# CSI2_PROTOCOL_ENGINE register map
Vendor: Texas Instruments
Peripheral module from a debugger description file (folder awr2544).
Registers are 32-bit, access per field, no defined reset value unless marked. A register's access mark holds for its fields unless they carry their own. Offsets are as the file gives them; lines under a group give offsets from that group; [hi:lo] are bit positions; {n}, {i} and the like mark numbered series; 'fields as' and 'values as' point back to an identical list; <NAME> marks a mode.

## CSI2_PROTOCOL_ENGINE (part 1 of 2) — CSI2 protocol engine (MIPI Display Serial Interface Protocole)
0x00 CSI2_REVISION ro — MODULE REVISION This register contains the IP revision code in binary coded digital. For example, we have: 0x01 = revision 0.1 and 0x21 = revision 2.1
  [7:0] REV — IP revision [7:4] Major revision [3:0] Minor revision
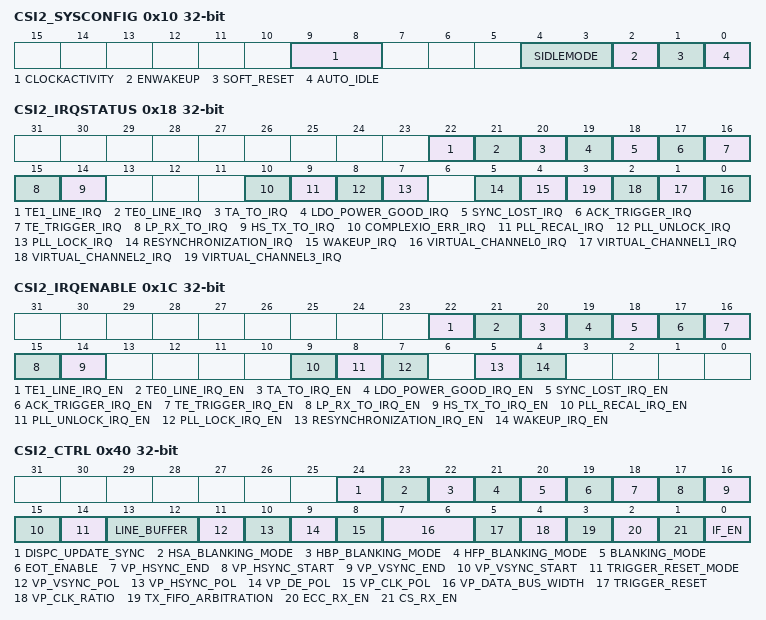
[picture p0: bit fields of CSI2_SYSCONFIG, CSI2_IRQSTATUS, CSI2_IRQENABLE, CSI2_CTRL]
0x10 CSI2_SYSCONFIG — SYSTEM CONFIGURATION REGISTER This register is the OCP-socket system configuration register.
  [9:8] CLOCKACTIVITY rw — Clocks activity during wake up mode period
    0=OCPFUNCOFF (OCP and Functional clocks can be switched off); 1=FUNCOFF (Functional clocks can be switched off and OCP clocks are maintained during wake up period); 2=OCPOFF (OCP clocks can be switched off and Functional clocks are maintained during wake up period); 3=OCPFUNCON (OCP and Functional clocks are maintained during wake up period)
  [4:3] SIDLEMODE rw — Slave interface power management, Idle req/ack control
    0=FIDLE (Force-idle. An idle request is acknowledged unconditionally); 1=NIDLE (No-idle. An idle request is never acknowledged); 2=SIDLE (Smart-idle. Acknowledgement to an idle request is given based on the internal activity of the module.)
  [2] ENWAKEUP rw — Wake-up mode enable bit
    0=WAKEUPDIS (Wakeup is disabled); 1=WAKEUPENB (Wakeup is enabled)
  [1] SOFT_RESET rw — Software reset. Set the bit to 1 to trigger a module reset. The bit is automatically reset by the hw. During reads return 0.
    0=NORMAL (Normal mode.); 1=RESET (The module is reset)
  [0] AUTO_IDLE rw — Internal OCP gating strategy
    0=FREE (OCP clock is free-running.); 1=GATED (Automatic OCP clock gating strategy is applied based on the OCP interface activity.)
0x14 CSI2_SYSSTATUS ro — SYSTEM STATUS REGISTER This register provides status information about the module, excluding the interrupt status register.
  [0] RESET_DONE — Internal reset monitoring
    0=RESETONGOING (Internal module reset is on going.); 1=RESETCOMPLETED
0x18 CSI2_IRQSTATUS — INTERRUPT STATUS REGISTER - All virtual channels + Complex IO + PLL This register associates one bit for each virtual channel in order to determine which virtual channel has generated the interrupt. The virtual channel shall be enabled for events to be generated on that virtual channel. If the virtual channel is disabled, the interrupt is not generated.
  [22] TE1_LINE_IRQ rw — The VSYNC and corresponding HSYNC pulses defined in CSI2_TE_HSYNC_NUMBER for the line TE1 have been received by the CSI2 protocol engine and have trigger the start of the data transfer to the peripheral.
    0=FALSE (READS: Event is false. WRITES: Status bit unchanged.); 1=TRUE (READS: Event is true (pending). WRITES: Status bit is reset.)
  [21] TE0_LINE_IRQ rw — The VSYNC and corresponding HSYNC pulses defined in CSI2_TE_HSYNC_NUMBER for the line TE0 have been received by the CSI2 protocol engine and have trigger the start of the data transfer to the peripheral.
    values as TE1_LINE_IRQ
  [20] TA_TO_IRQ rw — Turn-around Time out.
    values as TE1_LINE_IRQ
  [19] LDO_POWER_GOOD_IRQ rw — Transition of the status signal LDOPWRGOOD from the CSI2PHY indicating a state change for the supply VDDALDOCSI2PLL from up to down or down to up.
    values as TE1_LINE_IRQ
  [18] SYNC_LOST_IRQ rw — Synchronization with Video port is lost (Video mode only)
    values as TE1_LINE_IRQ
  [17] ACK_TRIGGER_IRQ rw — Acknowledge Trigger
    values as TE1_LINE_IRQ
  [16] TE_TRIGGER_IRQ rw — Tearing Effect Trigger
    values as TE1_LINE_IRQ
  [15] LP_RX_TO_IRQ rw — Interrupt for Low Power Rx Time out
    values as TE1_LINE_IRQ
  [14] HS_TX_TO_IRQ rw — Interrupt for High Speed Tx Time out.
    values as TE1_LINE_IRQ
  [10] COMPLEXIO_ERR_IRQ ro — Error signaling from Complex IO: status of the complex IO errors received from the complex IO(events are defined in CSI2_COMPLEXIO_IRQSTATUS).
    0=FALSE (READS: Event is false.); 1=TRUE (READS: Event is true (pending).)
  [9] PLL_RECAL_IRQ rw — PLL recal event (assertion of CSI2Recal signal from the CSI2 PLL Control module)
    values as TE1_LINE_IRQ
  [8] PLL_UNLOCK_IRQ rw — PLL un-clock event (de-assertion of CSI2Lock signal from the CSI2 PLL Control module)
    values as TE1_LINE_IRQ
  [7] PLL_LOCK_IRQ rw — PLL clock event (assertion of CSI2Lock signal from the CSI2 PLL Control module)
    values as TE1_LINE_IRQ
  [5] RESYNCHRONIZATION_IRQ rw — Video mode resynchronization indicates to the software users that the video port works but the configuration of the timings for the display controller (DISPC) and for CSI2 Protocol engine may need to be modified to avoid the resynchronization to occur.
    values as TE1_LINE_IRQ
  [4] WAKEUP_IRQ rw — Wakeup
    values as TE1_LINE_IRQ
  [n] VIRTUAL_CHANNEL{n}_IRQ ro (n=0..3) — Virtual channel #{n}
    values as COMPLEXIO_ERR_IRQ
0x1C CSI2_IRQENABLE — INTERRUPT ENABLE REGISTER - This register associates one bit for each virtual channel in order to enable/disable each virtual channel individually.
  [all] fields
    0=DISABLE (Event is masked); 1=ENABLE (Event generates an interrupt when it occurs)
  [22] TE1_LINE_IRQ_EN rw — The VSYNC and corresponding HSYNC pulses defined in CSI2_TE_HSYNC_NUMBER for the line TE1 have been received by the CSI2 protocol engine and have trigger the start of the data transfer to the peripheral.
  [21] TE0_LINE_IRQ_EN rw — The VSYNC and corresponding HSYNC pulses defined in CSI2_TE_HSYNC_NUMBER for the line TE0 have been received by the CSI2 protocol engine and have trigger the start of the data transfer to the peripheral.
  [20] TA_TO_IRQ_EN rw — Turn-around Time out.
  [19] LDO_POWER_GOOD_IRQ_EN rw — Transition of the status signal LDOPWRGOOD from the CSI2PHY indicating a state change for the supply VDDALDOCSI2PLL from up to down or down to up.
  [18] SYNC_LOST_IRQ_EN rw — Synchronization with Video port is lost (Video mode only)
  [17] ACK_TRIGGER_IRQ_EN rw — Acknowledge trigger
  [16] TE_TRIGGER_IRQ_EN rw — Tearing Effect trigger
  [15] LP_RX_TO_IRQ_EN rw — Interrupt for Low Power Rx Time out.
  [14] HS_TX_TO_IRQ_EN rw — Interrupt for High Speed Tx Time out.
  [9] PLL_RECAL_IRQ_EN rw — PLL recal event (assertion of CSI2Recal signal from the CSI2 PLL Control module)
  [8] PLL_UNLOCK_IRQ_EN rw — PLL un-clock event (de-assertion of CSI2Lock signal from the CSI2 PLL Control module)
  [7] PLL_LOCK_IRQ_EN rw — PLL clock event (assertion of CSI2Lock signal from the CSI2 PLL Control module)
  [5] RESYNCHRONIZATION_IRQ_EN rw — Video mode resynchronization
  [4] WAKEUP_IRQ_EN rw — Wakeup
0x40 CSI2_CTRL — GLOBAL CONTROL REGISTER This register controls the CSI2 Protocol Engine module. This register shall not be modified dynamically (except IF_EN bit fields).
  [24] DISPC_UPDATE_SYNC rw — Determines if the Dispc_Update_Sync signal from the display controller is used.
    0=DISABLE (Dispc_Update_Sync signal is not used.); 1=ENABLE (Dispc_Update_Sync signal is used.)
  [23] HSA_BLANKING_MODE rw — Blanking mode
    0=COMMAND_PACKET_TX_FIFO (Packets in TX FIFO are sent during HSA blanking period of video mode or LPS is used.); 1=HS_BLANKING_PACKET_ONLY (LONG BLANKING PACKETS only are used during HSA blanking period of video mode.)
  [22] HBP_BLANKING_MODE rw — Blanking mode
    0=COMMAND_PACKET_TX_FIFO (Packets in TX FIFO are sent during HBP blanking period of video mode or LPS is used.); 1=HS_BLANKING_PACKET_ONLY (LONG BLANKING PACKETS only are used during HBP blanking period of video mode.)
  [21] HFP_BLANKING_MODE rw — Blanking mode
    0=COMMAND_PACKET_TX_FIFO (Packets in TX FIFO are sent during HFP blanking period of video mode or LPS is used.); 1=HS_BLANKING_PACKET_ONLY (LONG BLANKING PACKETS only are used during HFP blanking period of video mode.)
  [20] BLANKING_MODE rw
    0=LPS (LPS is used during blanking periods of video mode (except HSA, HBP, HFP defined in HSA_BLANKING_MODE, HBP_BLANKING_MODE AND HFP_BLANKING_MODE respectively) when there is no command mode data in TX FIFO ready to be sent. So blanking periods can be different during the frame depending on the TX FIFO.); 1=HS (LONG BLANKING PACKETS are used during blanking periods of video mode (except HSA, HBP, HFP defined in HSA_BLANKING_MODE, HBP_BLANKING_MODE AND HFP_BLANKING_MODE respectively) regardless of the packets present in the TX FIFO ready to be sent)
  [19] EOT_ENABLE rw — Enable EOT packets at the end of HS transmission.
    0=EOT_OFF (No EOT packets); 1=EOT_ON (EOT packet is sent at all HS to LP transitions.)
  [18] VP_HSYNC_END rw — HSYNC end pulse.
    0=DISABLE (Disabled. No HSYNC END short packet is generated.); 1=ENABLE (Enabled. While the HSYNC END pulse is detected, the associated short packet HSYNC END is generated.)
  [17] VP_HSYNC_START rw — HSYNC start pulse.
    0=DISABLE (Disabled. No HSYNC START short packet is generated.); 1=ENABLE (Enabled. While the HSYNC start pulse is detected, the associated short packet HSYNC START is generated.)
  [16] VP_VSYNC_END rw — VSYNC end pulse.
    0=DISABLE (Disabled. No VSYNC END short packet is generated.); 1=ENABLE (Enabled. While the VSYNC END pulse is detected, the associated short packet VSYNC END is generated.)
  [15] VP_VSYNC_START rw — VSYNC start pulse.
    0=DISABLE (Disabled. No VSYNC START short packet is generated.); 1=ENABLE (Enabled. While the VSYNC START pulse is detected, the associated short packet VSYNC START is generated.)
  [14] TRIGGER_RESET_MODE rw — Selection of the trigger reset mode
    0=SYNCHRONIZED (Synchronized: the mode is only valid if there is virtual channel using the video mode and it is active. The principal is to wait for the current video frame to be transferred on the link. Any data received after the VSYNC are ignored.); 1=IMMEDIATE (Immediate: all pending requests in TX FIFO are taken into account for transfer scheduling, the RX FIFO is ignored, and the data from video port are ignored as soon as possible. Only the current transfer on CSI2 link and already scheduled ones are transmitted. All the other transfers are discarded.)
  [13:12] LINE_BUFFER rw — Number of line buffers to be used while receiving data on the video port. The valid values are from 0 to CSI2_GNQ.VP1_NB_LINE_BUFFER.
    0=F0 (No line buffer); 1=F1 (1 line buffer); 2=F2 (2 line buffers)
  [11] VP_VSYNC_POL rw — VP vertical synchronization signal polarity
    0=LOW (VSYNC signal on the video port is active low.); 1=HIGH (VSYNC signal on the video port is active high.)
  [10] VP_HSYNC_POL rw — VP horizontal synchronization signal polarity
    0=LOW (HSYNC signal on the video port is active low.); 1=HIGH (HSYNC signal on the video port is active high.)
  [9] VP_DE_POL rw — VP data enable signal polarity
    0=LOW (DE signal on the video port is active low.); 1=HIGH (DE signal on the video port is active high.)
  [8] VP_CLK_POL rw — VP clock polarity
    0=FALLING (The CSI2 Protocol Engine module captures the data on the VP on the pixel clock falling edge. The module connected to the VP shall drive the data on the pixel clock rising edge.); 1=RISING (The CSI2 Protocol Engine module captures the data on the VP on the pixel clock raising edge. The module connected to the VP shall drive the data on the pixel clock falling edge.)
  [7:6] VP_DATA_BUS_WIDTH rw — Defines the size of the video port data bus
    0=F16 (16-bits data width (LSB of the 24-bit video port data bus)); 1=F18 (18-bits data width (LSB of the 24-bit video port data bus)); 2=F24 (24-bits data width (LSB of the 24-bit video port data bus))
  [5] TRIGGER_RESET rw — Send the reset trigger to the peripheral.
    0=DISABLE (READS: Reset trigger generation is completed. It is reset by HW when it is completed. WRITES: Cancellation of the request for Reset trigger generation (maybe too late since it is already on going)); 1=ENABLE (READS: Generation of the reset trigger has been requested by user (could be on going but not completed yet). WRITES: Request for Reset trigger to be sent to the peripheral.)
  [4] VP_CLK_RATIO rw — The field indicates the clock ratio between VP.CLK and VP.PCLK. The clock VP.PCLK is generated from VP.CLK. It is divided down. The information is only used when the video port is used to provide data in command mode. In the case of video mode, it is not used.
    0=RATIO2 (The clock VP.PCLK is the clock VP.CLK divided by 2. The duty cycle of VP.PCLK is 50/50.); 1=RATIO3ANDHIGHER (The clock VP.PCLK is the clock VP.CLK divided by 3 or more. The duty cycle of VP.PCLK is not 50/50 for odd ratio numbers (3,5,7,...).)
  [3] TX_FIFO_ARBITRATION rw — Defines the arbitration scheme for granting the virtual channel pending ready requests in the TX FIFO
    0=ROUNDROBIN (Round-Robin Scheme is used); 1=SEQUENTIAL (Sequential Scheme is used)
  [2] ECC_RX_EN rw — Enables the Error Correction Code check for the received header (short and long packets for all virtual channel ids).
    0=DISABLE (Disabled); 1=ENABLE (Enabled)
  [1] CS_RX_EN rw — Enables the checksum check for the received payload (long packet only for all virtual channel ids).
    0=DISABLE (Disabled); 1=ENABLE (Enabled)
  [0] IF_EN rw — Enables the module. When the module is disabled the signals from the complex IO are gated (no updates of the interrupt status register). It is not possible to change the bit-fields in the register CSI2_CTRL except IF_EN when it is enabled. All the other registers can be changed except the ones that require CSI2_VC_CTRL.VC_EN to be equal to 0 to be modified.
    0=DISABLE (The interface is disabled. If one of the virtual channel uses the video mode with the video port to receive the data, the CSI2 protocol engines is disabled when the next VSYNC is received and all the data in the FIFO for the other virtual channels in command mode are sent to the peripherals (if BTA_EN is enabled, the CSI2 protocol needs to wait for the response and BTA from the peripheral before disabling all the internal logic since an acknowledge is requested).); 1=ENABLE (The interface is enabled immediately, the data acquisition on the video port starts on the next VSYNC (video mode) or first data received in the Slave port FIFO (command mode).)
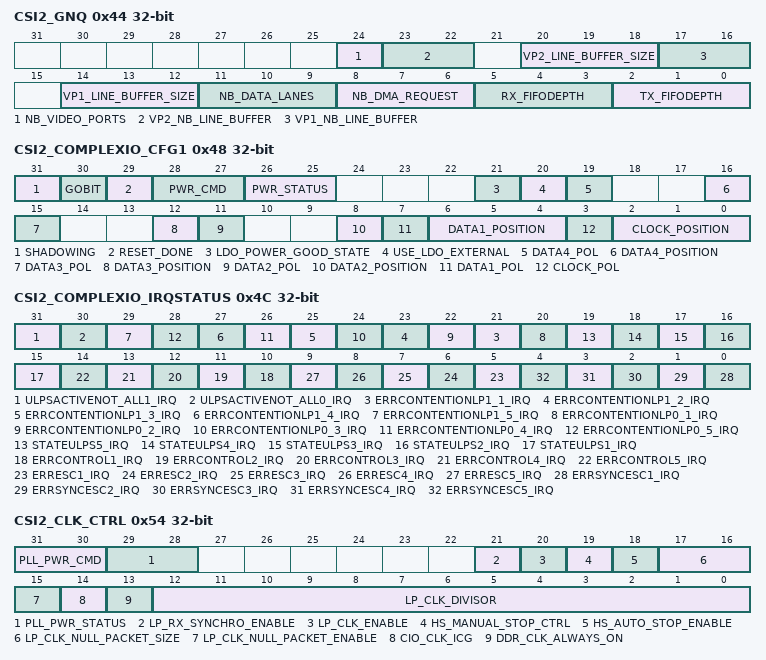
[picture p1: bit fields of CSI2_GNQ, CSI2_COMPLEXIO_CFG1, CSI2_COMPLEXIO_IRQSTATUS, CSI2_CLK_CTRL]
0x44 CSI2_GNQ ro — GENERIC PARAMETER REGISTER This register provide a way to read the generic parameters used in the design.
  [24] NB_VIDEO_PORTS — Number of video ports
    0=SINGLE_VP (Video port 1 only is present); 1=DUAL_VP (Video port 1 and video port 2 are present)
  [23:22] VP2_NB_LINE_BUFFER — Determines the number of video buffer lines associated to video port #2.
    0=F0 (No line buffer); 1=F1 (1 line buffer of the size defined in LINE_BUFFER_SIZE); 2=F2 (2 line buffers of the size defined in LINE_BUFFER_SIZE)
  [20:18] VP2_LINE_BUFFER_SIZE — Determines the video line buffer size associated to video port #2 .
    1=F1 (512x24-bits, 682x18-bits, 768x16bits (memory of 384x32-bits)); 2=F2 (682x24-bits, 910x18-bits, 1024x16bits (memory of 512x32-bits)); 3=F3 (853x24-bits, 1137x18-bits, 1280x16bits (memory of 640x32-bits)); 4=F4 (1024x24-bits, 1365x18-bits, 1536x16bits (memory of 768x32-bits)); 5=F5 (1194x24-bits, 1592x18-bits, 1792x16bits (memory of 896x32-bits)); 6=F6 (1365x24-bits, 1820x18-bits, 2048x16bits (memory of 1024x32-bits))
  [17:16] VP1_NB_LINE_BUFFER — Determines the number of video buffer lines associated to video port #1.
    values as VP2_NB_LINE_BUFFER
  [14:12] VP1_LINE_BUFFER_SIZE — Determines the video line buffer size associated to video port #1 .
    values as VP2_LINE_BUFFER_SIZE
  [11:9] NB_DATA_LANES — Determines the number of data lanes supported by the CSI2 protocol engine .
    1=F1 (1 Data lane); 2=F2 (2 Data lanes); 3=F3 (3 Data lanes); 4=F4 (4 Data lanes)
  [8:6] NB_DMA_REQUEST — Determines the number of DMA_REQ signals.
    0=F0 (No DMA request); 1=F1 (1 DMA request); 2=F2 (2 DMA requests); 3=F3 (3 DMA requests); 4=F4 (4 DMA requests)
  [5:3] RX_FIFODEPTH — Determines the data RX FIFO depth (32-bit words) on the slave port.
    4=F32 (32x 33 bits); 5=F64 (64x 33 bits); 6=F128 (128 x 33 bits); 7=F256 (256 x 33 bits)
  [2:0] TX_FIFODEPTH — Determines the data TX FIFO depth (33-bit words) on the slave port.
    values as RX_FIFODEPTH
0x48 CSI2_COMPLEXIO_CFG1 — COMPLEXIO CONFIGURATION REGISTER for the complex IO This register contains the lane configuration for the order and position of the lanes (clock and data) and the polarity order for the control of the PHY differential signals in addition to the control bit for the power FSM.
  [31] SHADOWING rw — Shadowing configuration.
    0=DISABLE (Disabled. The writes to the first 3 registers of the complex IO address map is done like the other SCP registers.); 1=ENABLE (Enabled. The writes to the first 3 registers of the complex IO address map is done only when the GObit is set and when the signal DISPCUpdataSync from the display controller module is active.)
  [30] GOBIT rw — Allows the synchronized update of the shadow registers when the signal DISPCUpdateSync is active.
    0=RESET (Resets the GOBIT. The hardware has finished the update of the shadow SCP registers. The bit is reset by Hardware. The SW can reset the bit in case the user decides to abort it. There is no guarantee that the SW reset is done before the transfer of the values to the complex IO.); 1=SET (Set the GOBIT. Only when the transfer of the new values for the three first registers is completed (3, 2, 1, or 0 transfers are performed based on the number of registers to update), the GOBIT is reset. The DISPCUpdateSync signal is used to synchronize the update. The bit shall be set only when it is in reset state.)
  [29] RESET_DONE ro — Internal reset monitoring of the power domain using the PPI byte clock from the complex IO
    values as CSI2_SYSSTATUS.RESET_DONE
  [28:27] PWR_CMD rw — Command for power control of the complex IO
    0=STATE_OFF (Command to change to OFF state); 1=STATE_ON (Command to change to ON state); 2=STATE_ULP (Command to change to Ultra Low Power state)
  [26:25] PWR_STATUS ro — Status of the power control of the complex IO
    0=STATE_OFF (Complex IO in OFF state); 1=STATE_ON (Complex IO in ON state); 2=STATE_ULP (Complex IO in Ultra Low Power state)
  [21] LDO_POWER_GOOD_STATE ro — Indicates the state of the signal LDOPWRGOOD. VDDALDOCSI2PLL: 1.2V power supply for the PLL. The voltage is supplied by the internal or external LDO. The interrupt LDO_POWER_GOOD_IRQ is generated when a transition is detected on the signal LDOPWRGOOD from the CSI2PHY.
    0=SUPPLYDOWN (VDDALDOCSI2PLL power supply is down); 1=SUPPLYUP (VDDALDOCSI2PLL power supply is up)
  [20] USE_LDO_EXTERNAL rw — Select the external LDO for the CSI2PHY.
    0=INTERNALLDO (CSI2PHY internal LDO is used.); 1=EXTERNALLDO (External LDO is used. CSI2PHY LDO is tri-stated.)
  [19] DATA4_POL rw — +/- differential pin order of DATA lane 4.
    0=PLUSMINUS (+/- pin order (CSI2.DX=+ and CSI2.DY=-)); 1=MINUSPLUS (-/+ pin order (CSI2.DX=- and CSI2.DY=+))
  [16] DATA4_POSITION rw — Position and order of the DATA lane 4.
  [15] DATA3_POL rw — +/- differential pin order of DATA lane 3.
    values as DATA4_POL
  [12] DATA3_POSITION rw — Position and order of the DATA lane 3.
  [11] DATA2_POL rw — +/- differential pin order of DATA lane 2.
    values as DATA4_POL
  [8] DATA2_POSITION rw — Position and order of the DATA lane 2.
  [7] DATA1_POL rw — +/- pin differential pin order of DATA lane 1
    values as DATA4_POL
  [6:4] DATA1_POSITION rw — Position and order of the DATA lane 1. The data lane 1 is always present.
    {v}=POSITION_{v} (Data lane 1 is at the position {v}.) (v=1..5)
  [3] CLOCK_POL rw — +/- differential pin order of CLOCK lane.
    values as DATA4_POL
  [2:0] CLOCK_POSITION rw — Position and order of the CLOCK lane. 0, 5, 6 and 7 are reserved. The clock lane is always present but can not be at the position 5 even if the COMPLEX IO consists of 5 lanes.
    {v}=POSITION_{v} (Clock lane is at the position {v}.) (v=1..4)
0x4C CSI2_COMPLEXIO_IRQSTATUS — INTERRUPT STATUS REGISTER - All errors from complex IO
  [all] fields
    values as CSI2_IRQSTATUS.TE1_LINE_IRQ
  [31] ULPSACTIVENOT_ALL1_IRQ rw — All the ULPSActiveNOT signals corresponding to the lanes with TXULPSExit being high are high.
  [30] ULPSACTIVENOT_ALL0_IRQ rw — All signals ULPSActiveNOT are 0
  [2n+19] ERRCONTENTIONLP1_{n}_IRQ rw (n=1..5) — Contention LP1 error for lane #{n}
  [2n+18] ERRCONTENTIONLP0_{n}_IRQ rw (n=1..5) — Contention LP0 error for lane #{n}
  [19] STATEULPS5_IRQ rw — Lane #5 in Ultra Low Power State
  [18] STATEULPS4_IRQ rw — Lane #4 in Ultra Low Power Mode
  [17] STATEULPS3_IRQ rw — Lane #3 in Ultra Low Power State
  [16] STATEULPS2_IRQ rw — Lane #2 in Ultra Low Power State
  [15] STATEULPS1_IRQ rw — Lane #1 in Ultra Low Power State
  [n+9] ERRCONTROL{n}_IRQ rw (n=1..5) — Control error for lane #{n}
  [n+4] ERRESC{n}_IRQ rw (n=1..5) — Escape entry error for lane #{n}
  [n-1] ERRSYNCESC{n}_IRQ rw (n=1..5) — Low power Data transmission synchronization error for lane #{n}
0x50 CSI2_COMPLEXIO_IRQENABLE — INTERRUPT ENABLE REGISTER - All errors from complex IO
  [31] ULPSACTIVENOT_ALL1_IRQ_EN rw — All the ULPSActiveNOT signals corresponding to the lanes with TXULPSExit being high are high.
    values as the fields of CSI2_IRQENABLE
  [30] ULPSACTIVENOT_ALL0_IRQ_EN rw — All signals ULPSActiveNOT are 0
    values as the fields of CSI2_IRQENABLE
  [2n+19] ERRCONTENTIONLP1_{n}_IRQ_EN rw (n=1..5) — Contention LP1 error for lane #{n}
    values as the fields of CSI2_IRQENABLE
  [n+11] RESERVED{n} ro (n=14..18) — Write 0's for future compatibility. Reads returns 0.
  [2n+18] ERRCONTENTIONLP0_{n}_IRQ_EN rw (n=1..5) — Contention LP0 error for lane #{n}
    values as the fields of CSI2_IRQENABLE
  [n+14] STATEULPS{n}_IRQ_EN rw (n=1..5) — Lane #{n} in Ultra Low Power State
    values as the fields of CSI2_IRQENABLE
  [n+9] ERRCONTROL{n}_IRQ_EN rw (n=1..5) — Control error for lane #{n}
    values as the fields of CSI2_IRQENABLE
  [n+4] ERRESC{n}_IRQ_EN rw (n=1..5) — Escape entry error for lane #{n}
    values as the fields of CSI2_IRQENABLE
  [n-1] ERRSYNCSESC{n}_IRQ_EN rw (n=1..5) — Low power Data transmission synchronization error for lane #{n}
    values as the fields of CSI2_IRQENABLE
0x54 CSI2_CLK_CTRL — CLOCK CONTROL This register controls the CLOCK GENERATION. The register can be modified only when IF_EN is reset.
  [31:30] PLL_PWR_CMD rw — Command for power control of the CSI2 PLL Control module
    0=STATE_OFF (Command to change to OFF state); 1=STATE_ON_HSCLK (Command to change to ON state for PLL only (HSDIVISER is OFF)); 2=STATE_ON_ALL (Command to change to ON state for both PLL and HSDIVISER); 3=STATE_ON_DIV (Command to change to ON state for both PLL and HSDIVISER (no clock output to the CSI2 complex IO))
  [29:28] PLL_PWR_STATUS ro — Status of the power control of the CSI2 PLL Control module
    0=STATE_OFF (CSI2 PLL Control module in OFF state); 1=STATE_ON_HSCLK (CSI2 PLL Control module in ON state for PLL only (HSDIVISER is OFF)); 2=STATE_ON_ALL (CSI2 PLL Control module in ON state for both PLL and HSDIVISER); 3=STATE_ON_DIV (CSI2 PLL Control module in ON state for both PLL and HSDIVISER (no clock output to the CSI2 complex IO))
  [21] LP_RX_SYNCHRO_ENABLE rw — Defines if the functional is higher or lower than 30 MHz. The information is used to define synchronization to be used for RxValidEsc.
    0=LOWSPEED (The CSI2 functional clock is equal or slower than 30 MHz. The synchronization is falling/rising.); 1=HIGHSPEED (The CSI2 functional clock is higher than 30 MHz. The synchronization is rising/rising.)
  [20] LP_CLK_ENABLE rw — Controls the gating of the TXCLKESC clock.
    0=DISABLE (Disabled. The clock is not generated. The value of LP_CLK_DIVISOR is not used and does not need to be programmed.); 1=ENABLE (Enabled. The clock is generated. The value of LP_CLK_DIVISOR is used and needs to be programmed.)
  [19] HS_MANUAL_STOP_CTRL rw — In case HS_AUTO_STOP_ENABLE=0, the bit-field allows manual control of the assertion/de-assertion of the signal CSI2StopClk by the user.
    0=DEASSERTION (CSI2StopClk de-assertion unconditionally.); 1=ASSERTION (CSI2StopClk assertion unconditionally.)
  [18] HS_AUTO_STOP_ENABLE rw — Enables the automatic assertion/de-assertion of CSI2StopClk signal.
    0=DISABLE (Auto mode disabled.); 1=ENABLE (Auto mode enabled.)
  [17:16] LP_CLK_NULL_PACKET_SIZE rw — Indicates the size of LP NULL Packets to be sent automatically when after the last LP packet transfer. It is used by the receiver to drain its internal pipeline. The valid values are from 0 to 3 bytes for the payload size.
  [15] LP_CLK_NULL_PACKET_ENABLE rw — Enables the generation of NULL packet in low speed.
    0=DISABLE (Disabled. The NULL packet is not sent in LP mode after the last LP packet.); 1=ENABLE (Enabled. The NULL packet is sent in LP mode after the last LP packet.)
  [14] CIO_CLK_ICG rw — Gates SCPClk clock provided to CSI2-PHY and PLL-CTRL module.
    0=DISABLE (Disabled. SCPClk is not generated. It remains at 0.); 1=ENABLE (Enabled. SCPClk is generated (OCP_CLK/4))
  [13] DDR_CLK_ALWAYS_ON rw — Defines if the DDR clock is also sent when there is no HS packets sent to the peripheral (low power mode). So TXRequest for the clock lane is not de-asserted.
    0=DISABLE (Disabled. The DDR clock is only provided when HS packets are sent.); 1=ENABLE (Enabled. The DDR clock is always sent to the peripheral regardless of the state of the data lanes (HS or LS mode).)
  [12:0] LP_CLK_DIVISOR rw — Defines the ratio to be used for the generation of the Low Power mode clock from CSI2 functional clock. The supported values are from 1 to 8191(the value 0 is invalid). The output frequency shall be in the range between 20 MHz and 32 kHz.
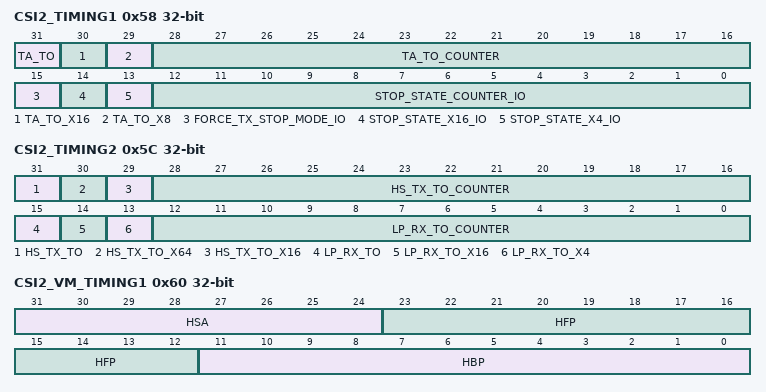
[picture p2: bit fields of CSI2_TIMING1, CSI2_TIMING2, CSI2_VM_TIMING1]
0x58 CSI2_TIMING1 rw — TIMING1 REGISTER This register controls the CSI2 Protocol Engine module timers. Any bit-field can be modified while CSI2_CTRL.IF_EN is set to '1'. It is used to indicate the number of CSI2_CLK functional clock cycles for the timers FORCE_TX_STOP_TIMER and TA_TO_TIMER
  [31] TA_TO — Enables the turn-around timer
    0=DEASSERTION (Turn-around counter is disabled.); 1=ASSERTION (Turn-around counter is enabled (required to receive TA interrupt in case the turn-around procedure is not successful).)
  [30] TA_TO_X16 — Multiplication factor for the number of CSI2_CLK functional clock cycles defined in TA_TO_COUNTER bit-field
    0=DISABLE (The number of CSI2_CLK functional clock cycles defined in TA_TO_COUNTER is multiplied by 1x); 1=ENABLE (The number of CSI2_CLK functional clock cycles defined in TA_TO_COUNTER is multiplied by 16x)
  [29] TA_TO_X8 — Multiplication factor for the number of CSI2_CLK functional clock cycles defined in TA_TO_COUNTER bit-field
    0=DISABLE (The number of CSI2_CLK functional clock cycles defined in TA_TO_COUNTER is multiplied by 1x); 1=ENABLE (The number of CSI2_CLK functional clock cycles defined in TA_TO_COUNTER is multiplied by 8x)
  [28:16] TA_TO_COUNTER — Turn around counter. It indicates the number of CSI2_CLK function clock to wait for the change of the Direction PPI signal according to the TurnRequest signal The value is from 0 to 8191.
  [15] FORCE_TX_STOP_MODE_IO — Control of ForceTxStopMode signal
    0=DEASSERTION (De-assertion of ForceTxStopMode. The HW reset the bit at the end of the ForceTXStopMode assertion. The SW can reset the bit in order to stop the assertion of the ForceTXStopMode signal prior to the completion of the period.); 1=ASSERTION (Assertion of ForceTxStopMode)
  [14] STOP_STATE_X16_IO — Multiplication factor for the number of CSI2_CLK functional clock cycles defined in STOP_STATE_COUNTER_IO bit-field
    0=DISABLE (The number of CSI2_CLK functional clock cycles defined in STOP_STATE _COUNTER_IO is multiplied by 1x); 1=ENABLE (The number of CSI2_CLK functional clock cycles defined in STOP_STATE _COUNTER_IO is multiplied by 16x)
  [13] STOP_STATE_X4_IO — Multiplication factor for the number of CSI2_CLK functional clock cycles defined in STOP_STATE_COUNTER_IO bit-field
    0=DISABLE (The number of CSI2_CLK functional clock cycles defined in STOP_STATE _COUNTER is multiplied by 1x); 1=ENABLE (The number of CSI2_CLK functional clock cycles defined in STOP_STATE _COUNTER_IO is multiplied by 4x)
  [12:0] STOP_STATE_COUNTER_IO — Stop state counter. It indicates the number of CSI2_CLK function clock to assert ForceTXStopMode signal. The value is from 0 to 8191.
0x5C CSI2_TIMING2 rw — TIMING2 REGISTER This register controls the CSI2 Protocol Engine module timers. Any bit-field can be modified while CSI2_CTRL.IF_EN is set to '1'. It is used to indicate the number of CSI2_CLK functional clock cycles for the timers HS_TX_TIMER and LP_RX_TIMER
  [31] HS_TX_TO — Enables the HS TX timer.
    0=DEASSERTION (Time-out counter is disabled.); 1=ASSERTION (Time-out counter is enabled (required to receive TA interrupt in case the turn-around procedure is not successful).)
  [30] HS_TX_TO_X64 — Multiplication factor for the number of BYTE_CLK functional clock cycles defined in HS_TX_COUNTER bit-field
    0=DISABLE (The number of BYTE_CLK functional clock cycles defined in HS_TX_TO_COUNTER is multiplied by 1x); 1=ENABLE (The number of BYTE_CLK functional clock cycles defined in HS_TX_TO_COUNTER is multiplied by 64x)
  [29] HS_TX_TO_X16 — Multiplication factor for the number of BYTE_CLK functional clock cycles defined in HS_TX_COUNTER bit
    0=DISABLE (The number of BYTE_CLK functional clock cycles defined in HS_TX_TO_COUNTER is multiplied by 1x); 1=ENABLE (The number of BYTE_CLK functional clock cycles defined in HS_TX_TO_COUNTER is multiplied by 16x)
  [28:16] HS_TX_TO_COUNTER — HS_TX_TIMER counter. It indicates the number of BYTE_CLK function clock for the HS TX timer. The value is from 0 to 8191.
  [15] LP_RX_TO — Enables the LP RX timer.
    values as CSI2_TIMING1.TA_TO
  [14] LP_RX_TO_X16 — Multiplication factor for the number of CSI2_CLK functional clock cycles defined in LP_RX_COUNTER bit-field
    0=DISABLE (The number of CSI2_CLK functional clock cycles defined in LP_RX_TO_COUNTER is multiplied by 1x); 1=ENABLE (The number of CSI2_CLK functional clock cycles defined in LP_RX_TO_COUNTER is multiplied by 16x)
  [13] LP_RX_TO_X4 — Multiplication factor for the number of CSI2_CLK functional clock cycles defined in LP_RX_COUNTER bit
    0=DISABLE (The number of CSI2_CLK functional clock cycles defined in LP_RX_TO_COUNTER is multiplied by 1x); 1=ENABLE (The number of CSI2_CLK functional clock cycles defined in LP_RX_TO_COUNTER is multiplied by 4x)
  [12:0] LP_RX_TO_COUNTER — LP_RX_TIMER counter. It indicates the number of CSI2_CLK function clock for the LP RX timer. The value is from 0 to 8191.
0x60 CSI2_VM_TIMING1 rw — VIDEO MODE TIMING REGISTER This register defines the video mode timing.
  [31:24] HSA — Defines the horizontal Sync active period used in video mode in number of byte clock cycles (PPI clock) The supported values are from 0 to 255.
  [23:12] HFP — Defines the horizontal front porch used in video mode in number of byte clock cycles (PPI clock) The supported values are from 0 to 4095
  [11:0] HBP — Defines the horizontal back porch used in video mode in number of byte clock cycles (PPI clock) The supported values are from 0 to 4095
